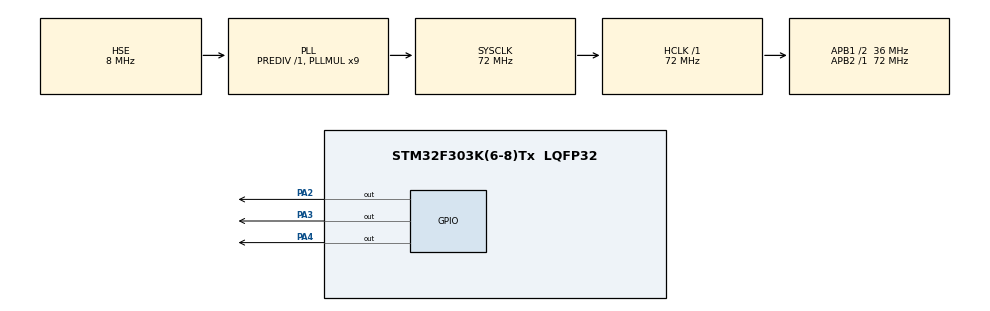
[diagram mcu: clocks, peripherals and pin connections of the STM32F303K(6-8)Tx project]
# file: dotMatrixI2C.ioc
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Mcu.Family=STM32F3
Mcu.Name=STM32F303K(6-8)Tx
Mcu.Package=LQFP32
NVIC.PriorityGroup=NVIC_PRIORITYGROUP_4
PA13.GPIO_Label=SWDIO
PA13.Mode=Serial_Wire
PA13.Signal=SYS_JTMS-SWDIO
PA14.GPIO_Label=SWCLK
PA14.Mode=Serial_Wire
PA14.Signal=SYS_JTCK-SWCLK
PA15.GPIO_Label=VCP_RX
PA15.Signal=USART2_RX
PA2.Signal=GPIO_Output
PA3.Signal=GPIO_Output
PA4.Signal=GPIO_Output
PF0\ /\ OSC_IN.GPIO_Label=MCO
PF0\ /\ OSC_IN.Mode=HSE-External-Oscillator
PF0\ /\ OSC_IN.Signal=RCC_OSC_IN
PF1\ /\ OSC_OUT.Mode=HSE-External-Oscillator
PF1\ /\ OSC_OUT.Signal=RCC_OSC_OUT
ProjectManager.HeapSize=0x200
ProjectManager.StackSize=0x400
ProjectManager.TargetToolchain=STM32CubeIDE
RCC.AHBFreq_Value=72000000
RCC.APB1CLKDivider=RCC_HCLK_DIV2
RCC.APB1Freq_Value=36000000
RCC.APB1TimFreq_Value=72000000
RCC.APB2Freq_Value=72000000
RCC.APB2TimFreq_Value=72000000
RCC.CortexFreq_Value=72000000
RCC.HCLKFreq_Value=72000000
RCC.HSE_VALUE=8000000
RCC.HSI_VALUE=8000000
RCC.PLLMUL=RCC_PLL_MUL9
RCC.PLLSourceVirtual=RCC_PLLSOURCE_HSE
RCC.SYSCLKFreq_VALUE=72000000
RCC.SYSCLKSourceVirtual=RCC_SYSCLKSOURCE_PLLCLK
board=NUCLEO-F303K8

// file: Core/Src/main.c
/* USER CODE BEGIN Header */
/**
  ******************************************************************************
  * @file           : main.c
  * @brief          : Main program body
  ******************************************************************************
  ** This notice applies to any and all portions of this file
  * that are not between comment pairs USER CODE BEGIN and
  * USER CODE END. Other portions of this file, whether
  * inserted by the user or by software development tools
  * are owned by their respective copyright owners.
  *
  * COPYRIGHT(c) 2019 STMicroelectronics
  *
  * Redistribution and use in source and binary forms, with or without modification,
  * are permitted provided that the following conditions are met:
  *   1. Redistributions of source code must retain the above copyright notice,
  *      this list of conditions and the following disclaimer.
  *   2. Redistributions in binary form must reproduce the above copyright notice,
  *      this list of conditions and the following disclaimer in the documentation
  *      and/or other materials provided with the distribution.
  *   3. Neither the name of STMicroelectronics nor the names of its contributors
  *      may be used to endorse or promote products derived from this software
  *      without specific prior written permission.
  *
  * THIS SOFTWARE IS PROVIDED BY THE COPYRIGHT HOLDERS AND CONTRIBUTORS "AS IS"
  * AND ANY EXPRESS OR IMPLIED WARRANTIES, INCLUDING, BUT NOT LIMITED TO, THE
  * IMPLIED WARRANTIES OF MERCHANTABILITY AND FITNESS FOR A PARTICULAR PURPOSE ARE
  * DISCLAIMED. IN NO EVENT SHALL THE COPYRIGHT HOLDER OR CONTRIBUTORS BE LIABLE
  * FOR ANY DIRECT, INDIRECT, INCIDENTAL, SPECIAL, EXEMPLARY, OR CONSEQUENTIAL
  * DAMAGES (INCLUDING, BUT NOT LIMITED TO, PROCUREMENT OF SUBSTITUTE GOODS OR
  * SERVICES; LOSS OF USE, DATA, OR PROFITS; OR BUSINESS INTERRUPTION) HOWEVER
  * CAUSED AND ON ANY THEORY OF LIABILITY, WHETHER IN CONTRACT, STRICT LIABILITY,
  * OR TORT (INCLUDING NEGLIGENCE OR OTHERWISE) ARISING IN ANY WAY OUT OF THE USE
  * OF THIS SOFTWARE, EVEN IF ADVISED OF THE POSSIBILITY OF SUCH DAMAGE.
  *
  ******************************************************************************
  */
/* USER CODE END Header */

#include "main.h"

/* USER CODE BEGIN Includes */

#include "max_matrix_stm32.h"

/* USER CODE END Includes */

void SystemClock_Config(void);
static void MX_GPIO_Init(void);

int main(void)
{

  /* MCU Configuration--------------------------------------------------------*/

  /* Reset of all peripherals, Initializes the Flash interface and the Systick. */
  HAL_Init();

  /* Configure the system clock */
  SystemClock_Config();

  /* Initialize all configured peripherals */
  MX_GPIO_Init();
  /* USER CODE BEGIN 2 */

  max_init (0x03);

//	write_char ('A',4);  // write 'A' on 4th display
//	write_char ('2',3);  // write '2' on 3rd display
//	write_char (3,2);  // print heart on 2nd display
//	write_char ('m',1);  // write 'm'on st display

  /* USER CODE END 2 */

  /* Infinite loop */
  /* USER CODE BEGIN WHILE */
  while (1)
  {
//		scroll_char ('P', 200, right);
		scroll_string ((uint8_t *) "Sensor x ", 10, left); //text, ms, direction

  }
  /* USER CODE END 3 */
}

void SystemClock_Config(void)
{
  RCC_OscInitTypeDef RCC_OscInitStruct = {0};
  RCC_ClkInitTypeDef RCC_ClkInitStruct = {0};

  /**Initializes the CPU, AHB and APB busses clocks
  */
  RCC_OscInitStruct.OscillatorType = RCC_OSCILLATORTYPE_HSE;
  RCC_OscInitStruct.HSEState = RCC_HSE_ON;
  RCC_OscInitStruct.HSEPredivValue = RCC_HSE_PREDIV_DIV1;
  RCC_OscInitStruct.HSIState = RCC_HSI_ON;
  RCC_OscInitStruct.PLL.PLLState = RCC_PLL_ON;
  RCC_OscInitStruct.PLL.PLLSource = RCC_PLLSOURCE_HSE;
  RCC_OscInitStruct.PLL.PLLMUL = RCC_PLL_MUL9;
  if (HAL_RCC_OscConfig(&RCC_OscInitStruct) != HAL_OK)
  {
    Error_Handler();
  }
  /**Initializes the CPU, AHB and APB busses clocks
  */
  RCC_ClkInitStruct.ClockType = RCC_CLOCKTYPE_HCLK|RCC_CLOCKTYPE_SYSCLK
                              |RCC_CLOCKTYPE_PCLK1|RCC_CLOCKTYPE_PCLK2;
  RCC_ClkInitStruct.SYSCLKSource = RCC_SYSCLKSOURCE_PLLCLK;
  RCC_ClkInitStruct.AHBCLKDivider = RCC_SYSCLK_DIV1;
  RCC_ClkInitStruct.APB1CLKDivider = RCC_HCLK_DIV2;
  RCC_ClkInitStruct.APB2CLKDivider = RCC_HCLK_DIV1;

  if (HAL_RCC_ClockConfig(&RCC_ClkInitStruct, FLASH_LATENCY_2) != HAL_OK)
  {
    Error_Handler();
  }
}

static void MX_GPIO_Init(void)
{
  GPIO_InitTypeDef GPIO_InitStruct = {0};

  /* GPIO Ports Clock Enable */
  __HAL_RCC_GPIOD_CLK_ENABLE();
  __HAL_RCC_GPIOA_CLK_ENABLE();

  /*Configure GPIO pin Output Level */
  HAL_GPIO_WritePin(GPIOA, GPIO_PIN_2|GPIO_PIN_3|GPIO_PIN_4, GPIO_PIN_RESET);

  /*Configure GPIO pins : PA2 PA3 PA4 */
  GPIO_InitStruct.Pin = GPIO_PIN_2|GPIO_PIN_3|GPIO_PIN_4;
  GPIO_InitStruct.Mode = GPIO_MODE_OUTPUT_PP;
  GPIO_InitStruct.Pull = GPIO_NOPULL;
  GPIO_InitStruct.Speed = GPIO_SPEED_FREQ_LOW;
  HAL_GPIO_Init(GPIOA, &GPIO_InitStruct);

}

void Error_Handler(void)
{
}

/************************ (C) COPYRIGHT STMicroelectronics *****END OF FILE****/
